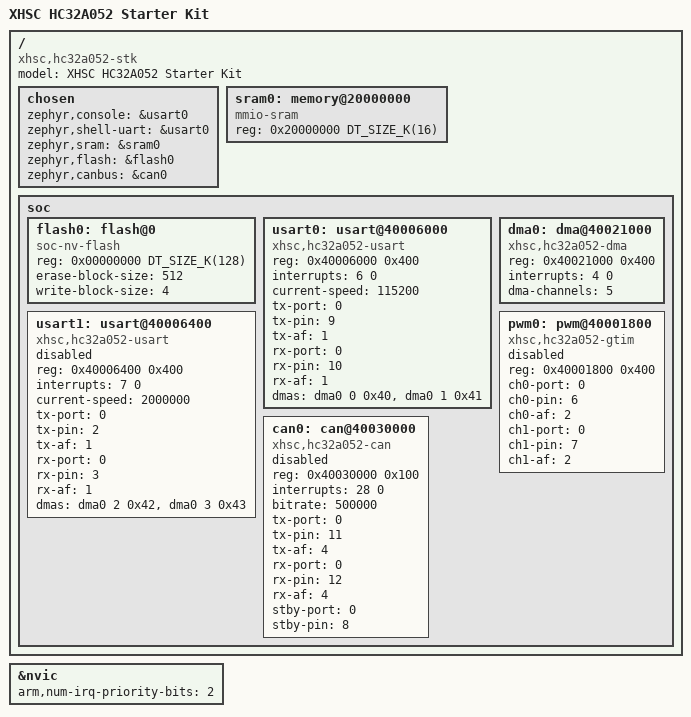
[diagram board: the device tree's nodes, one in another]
/*
 * SPDX-License-Identifier: Apache-2.0
 *
 * XHSC HC32A052 Starter Kit (STK-HC32A052).
 */

/dts-v1/;

#include <mem.h>
#include <arm/armv6-m.dtsi>

/ {
	compatible = "xhsc,hc32a052-stk";
	model = "XHSC HC32A052 Starter Kit";

	chosen {
		zephyr,console = &usart0;
		zephyr,shell-uart = &usart0;
		zephyr,sram = &sram0;
		zephyr,flash = &flash0;
		zephyr,canbus = &can0;
	};

	sram0: memory@20000000 {
		compatible = "mmio-sram";
		reg = <0x20000000 DT_SIZE_K(16)>;
	};

	soc {
		flash0: flash@0 {
			compatible = "soc-nv-flash";
			reg = <0x00000000 DT_SIZE_K(128)>;
			erase-block-size = <512>;
			write-block-size = <4>;
		};

		/* USART0: PA9 = TXD (AF1), PA10 = RXD (AF1). */
		usart0: usart@40006000 {
			compatible = "xhsc,hc32a052-usart";
			reg = <0x40006000 0x400>;
			interrupts = <6 0>;
			status = "okay";
			current-speed = <115200>;
			tx-port = <0>;
			tx-pin = <9>;
			tx-af = <1>;
			rx-port = <0>;
			rx-pin = <10>;
			rx-af = <1>;
			dmas = <&dma0 0 0x40>, <&dma0 1 0x41>;
			dma-names = "tx", "rx";
		};

		/* USART1: PA2 = TXD (AF1), PA3 = RXD (AF1). */
		usart1: usart@40006400 {
			compatible = "xhsc,hc32a052-usart";
			reg = <0x40006400 0x400>;
			interrupts = <7 0>;
			status = "disabled";
			current-speed = <2000000>;
			tx-port = <0>;
			tx-pin = <2>;
			tx-af = <1>;
			rx-port = <0>;
			rx-pin = <3>;
			rx-af = <1>;
			dmas = <&dma0 2 0x42>, <&dma0 3 0x43>;
			dma-names = "tx", "rx";
		};

		dma0: dma@40021000 {
			compatible = "xhsc,hc32a052-dma";
			reg = <0x40021000 0x400>;
			interrupts = <4 0>;
			status = "okay";
			dma-channels = <5>;
			#dma-cells = <2>;
		};

		/*
		 * GTIM0 compare/capture channels for PWM output:
		 * PA6 = CH0 (AF2), PA7 = CH1 (AF2).
		 * GTIM0 shares its silicon with BTIM0/1/2, GTIM1 with
		 * BTIM3/4/5; enabling both is not possible.
		 */
		pwm0: pwm@40001800 {
			compatible = "xhsc,hc32a052-gtim";
			reg = <0x40001800 0x400>;
			status = "disabled";
			#pwm-cells = <3>;
			ch0-port = <0>;
			ch0-pin = <6>;
			ch0-af = <2>;
			ch1-port = <0>;
			ch1-pin = <7>;
			ch1-af = <2>;
		};

		/*
		 * CAN: PA11 = CAN_TX (AF4), PA12 = CAN_RX (AF4),
		 * PA8 = transceiver STBY (driven low to enable).
		 * Disabled by default; enable it from an overlay once a
		 * transceiver is wired up.
		 */
		can0: can@40030000 {
			compatible = "xhsc,hc32a052-can";
			reg = <0x40030000 0x100>;
			interrupts = <28 0>;
			status = "disabled";
			bitrate = <500000>;
			tx-port = <0>;
			tx-pin = <11>;
			tx-af = <4>;
			rx-port = <0>;
			rx-pin = <12>;
			rx-af = <4>;
			stby-port = <0>;
			stby-pin = <8>;
		};
	};
};

&nvic {
	/* Cortex-M0+ implements 2 priority bits (__NVIC_PRIO_BITS). */
	arm,num-irq-priority-bits = <2>;
};
